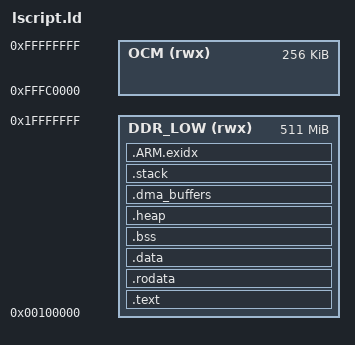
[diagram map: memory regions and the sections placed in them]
/*=============================================================================
 * lscript.ld — Buck HIL PS 固件链接脚本 (ZU3EG, Cortex-A53)
 *
 * 内存布局:
 *   DDR:  0x00100000 ~ 0x1FFFFFFF (511MB usable)
 *   OCM:  0xFFFC0000 ~ 0xFFFFFFFF (256KB, 用于初始启动栈)
 *
 * DMA 缓冲区在 .dma_buffers 段中, 64 字节对齐
 *=============================================================================*/

OUTPUT_FORMAT("elf64-littleaarch64", "elf64-bigaarch64", "elf64-littleaarch64")
OUTPUT_ARCH(aarch64)
ENTRY(_vector_table)
/* ENTRY(_start) — 由 FSBL 设置, 默认 _start / reset vector */

/* 64-bit AArch64 内存区域 (ZU3EG) */
MEMORY
{
    DDR_LOW  (rwx) : ORIGIN = 0x00100000, LENGTH = 0x1FF00000  /* 511 MB */
    OCM      (rwx) : ORIGIN = 0xFFFC0000, LENGTH = 0x00040000  /* 256 KB */
}

SECTIONS
{
    /*-------------------------------------------------------------------------
     * 代码段 — DDR 起始
     *-------------------------------------------------------------------------*/
    .text : {
        KEEP(*(.vectors))           /* 异常向量表 */
        *(.boot)
        *(.text)
        *(.text.*)
        *(.gnu.linkonce.t.*)
        *(.plt)
        *(.gnu_warning)
        *(.gcc_except_table)
    } > DDR_LOW

    /*-------------------------------------------------------------------------
     * 只读数据
     *-------------------------------------------------------------------------*/
    .rodata : {
        *(.rodata)
        *(.rodata.*)
        *(.gnu.linkonce.r.*)
    } > DDR_LOW

    /*-------------------------------------------------------------------------
     * 初始化数据
     *-------------------------------------------------------------------------*/
    .data : {
        __data_start = .;
        *(.data)
        *(.data.*)
        *(.gnu.linkonce.d.*)
        __data_end = .;
    } > DDR_LOW

    /*-------------------------------------------------------------------------
     * BSS (零初始化)
     *-------------------------------------------------------------------------*/
    .bss : {
        __bss_start = .;
        *(.bss)
        *(.bss.*)
        *(.gnu.linkonce.b.*)
        *(COMMON)
        __bss_end = .;
    } > DDR_LOW

    /*-------------------------------------------------------------------------
     * 堆 (lwIP 内存池, 协议缓冲)
     * 预留 256KB, 对齐 4KB
     *-------------------------------------------------------------------------*/
    .heap (NOLOAD) : {
        . = ALIGN(4096);
        __heap_start = .;
        . = . + 0x40000;           /* 256 KB */
        __heap_end = .;
    } > DDR_LOW

    /*-------------------------------------------------------------------------
     * DMA 缓冲区段 (64 字节对齐)
     * 16 × 64KB = 1MB
     *-------------------------------------------------------------------------*/
    .dma_buffers (NOLOAD) : {
        . = ALIGN(64);
        __dma_buffer_start = .;
        . = . + 0x100000;          /* 1 MB */
        __dma_buffer_end = .;
    } > DDR_LOW

    /*-------------------------------------------------------------------------
     * 栈 (EL1 运行时)
     * 预留 64KB
     *-------------------------------------------------------------------------*/
    .stack (NOLOAD) : {
        . = ALIGN(16);
        __stack_start = .;
        . = . + 0x10000;           /* 64 KB */
        __stack_end = .;
    } > DDR_LOW

    /*-------------------------------------------------------------------------
     * 调试信息
     *-------------------------------------------------------------------------*/
    /* DWARF debug sections */
    .debug          0 : { *(.debug) }
    .debug_line     0 : { *(.debug_line) }
    .debug_info     0 : { *(.debug_info) }
    .debug_abbrev   0 : { *(.debug_abbrev) }
    .debug_aranges  0 : { *(.debug_aranges) }
    .debug_frame    0 : { *(.debug_frame) }
    .debug_ranges   0 : { *(.debug_ranges) }

    /* ARM-specific unwind */
    .ARM.exidx : {
        __exidx_start = .;
        *(.ARM.exidx* .gnu.linkonce.armexidx.*)
        __exidx_end = .;
    } > DDR_LOW
}
